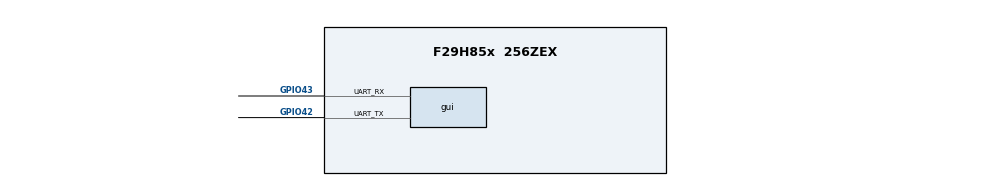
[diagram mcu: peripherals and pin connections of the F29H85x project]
/**
 * @cliArgs --device "F29H85x" --package "256ZEX" --part "F29H85x_256ZEX" --context "CPU1" --product "MCU_SDK_F29H85x@1.00.00.00"
 * @versions {"tool":"1.22.0+3877"}
 */

const divider15       = system.clockTree["PLL_REFDIV"];
divider15.divideValue = 1;

const multiplier1         = system.clockTree["PLL_IMULT"];
multiplier1.multiplyValue = 40;

const mux7       = system.clockTree["OSCCLKSRCSEL"];
mux7.inputSelect = "INTOSC2";

/**
 * Import the modules used in this configuration.
 */
const adc       = scripting.addModule("/driverlib/adc.js", {}, false);
const adc1      = adc.addInstance();
const asysctl   = scripting.addModule("/driverlib/asysctl.js");
const dlt       = scripting.addModule("/driverlib/dlt.js");
const gui       = scripting.addModule("/transfer/gui.js");

/**
 * Write custom configuration values to the imported modules.
 */
adc1.$name                    = "myADC0";
adc1.adcClockPrescaler        = "ADC_CLK_DIV_4_0";
adc1.enabledSOCs              = ["ADC_SOC_NUMBER0"];
adc1.soc0Channel              = "ADC_CH_ADCIN20";
adc1.soc0SampleWindow         = 140;
adc1.soc0Trigger              = "ADC_TRIGGER_EPWM1_SOCA";
adc1.enabledInts              = ["ADC_INT_NUMBER1"];
adc1.enableInterrupt1         = true;
adc1.registerInterrupts       = ["1"];
adc1.periphClock.$name        = "driverlib_perClock0";
adc1.periphConfig.$name       = "driverlib_perConfig0";
adc1.adcInt1.interruptHandler = "adcA1ISR";
scripting.suppress("SOC0 Channel selected has no device pin found\\.", adc1, "soc0Channel");

const analog  = scripting.addModule("/driverlib/analog.js", {}, false);
const analog1 = analog.addInstance({}, false);
analog1.$name = "myANALOGPinMux0";
adc1.analog   = analog1;

asysctl.analogReferenceAB  = "INTERNAL_3_3_V";
asysctl.analogReferenceCDE = "INTERNAL_3_3_V";
asysctl.enableTemperatureSensor = true;

dlt.enableTagFilter    = true;
dlt.startTagReference  = 0x5;
dlt.startTagMask       = 0xFFFF;
dlt.endTagMask         = 0xFFFF;
dlt.endTagReference     = 0x20;
dlt.enableInterrupt     = ["DLT_INT_FIFO_TRIG"];
dlt.setFIFOTriggerLevel = 128;
dlt.periphClock.$name  = "driverlib_perClock2";
dlt.periphConfig.$name = "driverlib_perConfig2";
dlt.registerInterrupts  = true;

gui.customlogger                                    = true;
gui.dltlogger                                       = true;
gui.guiProjectName                                  = "adc_tempsensor_dlt";
gui.exporter.$name                                  = "myEXPORT0";
gui.exporter.packageMode                            = "START/END";
gui.exporter.txStartByte                            = 0xAA;
gui.exporter.txEndByte                              = 0xFF;
gui.exporter.comsLinkModule.uart.uart_txPin.$assign = "GPIO42";
gui.exporter.comsLinkModule.uart.uart_rxPin.$assign = "GPIO43";
gui.exporter.comsLinkModule.txQual.$name            = "myGPIOQUAL0";
gui.exporter.comsLinkModule.rxQual.$name            = "myGPIOQUAL1";
gui.exporter.comsLinkModule.periphClock.$name       = "driverlib_perClock1";
gui.exporter.comsLinkModule.periphConfig.$name      = "driverlib_perConfig1";
gui.exporter.txKeyValuePairs.create(2);
gui.exporter.txKeyValuePairs[1].$name               = "DLTlog";
gui.exporter.txKeyValuePairs[1].keyValueID          = 49;
gui.exporter.txKeyValuePairs[1].valType             = "uint32_t";
gui.DLTModule.$name                                 = "myDLTLOG0";
